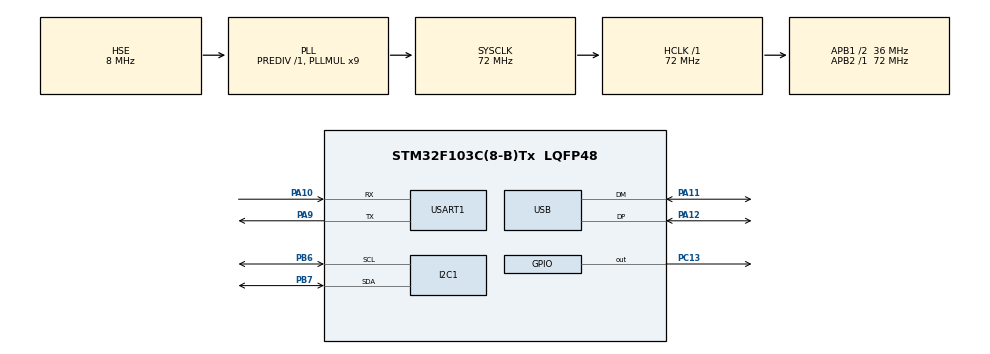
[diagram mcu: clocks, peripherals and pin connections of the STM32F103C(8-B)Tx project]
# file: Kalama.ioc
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FREERTOS.Tasks01=defaultTask,0,512,StartDefaultTask,Default,NULL,Dynamic,NULL,NULL
FREERTOS.configUSE_NEWLIB_REENTRANT=1
Mcu.Family=STM32F1
Mcu.Name=STM32F103C(8-B)Tx
Mcu.Package=LQFP48
NVIC.PriorityGroup=NVIC_PRIORITYGROUP_4
NVIC.TIM4_IRQn=true\:15\:0\:false\:false\:true\:false\:false\:true\:true
NVIC.TimeBase=TIM4_IRQn
NVIC.TimeBaseIP=TIM4
NVIC.USB_LP_CAN1_RX0_IRQn=true\:5\:0\:false\:false\:true\:true\:false\:true\:true
PA10.Mode=Asynchronous
PA10.Signal=USART1_RX
PA11.Mode=Device
PA11.Signal=USB_DM
PA12.Mode=Device
PA12.Signal=USB_DP
PA13.Mode=Trace_Asynchronous_SW
PA13.Signal=SYS_JTMS-SWDIO
PA14.Mode=Trace_Asynchronous_SW
PA14.Signal=SYS_JTCK-SWCLK
PA9.Mode=Asynchronous
PA9.Signal=USART1_TX
PB3.Mode=Trace_Asynchronous_SW
PB3.Signal=SYS_JTDO-TRACESWO
PB6.Mode=I2C
PB6.Signal=I2C1_SCL
PB7.Mode=I2C
PB7.Signal=I2C1_SDA
PC13-TAMPER-RTC.Signal=GPIO_Output
PC14-OSC32_IN.Mode=LSE-External-Oscillator
PC14-OSC32_IN.Signal=RCC_OSC32_IN
PC15-OSC32_OUT.Mode=LSE-External-Oscillator
PC15-OSC32_OUT.Signal=RCC_OSC32_OUT
PD0-OSC_IN.Mode=HSE-External-Oscillator
PD0-OSC_IN.Signal=RCC_OSC_IN
PD1-OSC_OUT.Mode=HSE-External-Oscillator
PD1-OSC_OUT.Signal=RCC_OSC_OUT
ProjectManager.HeapSize=0x4000
ProjectManager.StackSize=0x4000
ProjectManager.TargetToolchain=STM32CubeIDE
RCC.AHBFreq_Value=72000000
RCC.APB1CLKDivider=RCC_HCLK_DIV2
RCC.APB1Freq_Value=36000000
RCC.APB1TimFreq_Value=72000000
RCC.APB2Freq_Value=72000000
RCC.APB2TimFreq_Value=72000000
RCC.HCLKFreq_Value=72000000
RCC.PLLMUL=RCC_PLL_MUL9
RCC.SYSCLKFreq_VALUE=72000000
RCC.SYSCLKSource=RCC_SYSCLKSOURCE_PLLCLK
RCC.USBFreq_Value=48000000
RCC.USBPrescaler=RCC_USBCLKSOURCE_PLL_DIV1_5
USART1.VirtualMode=VM_ASYNC
USB_DEVICE.CLASS_NAME_FS=CDC
USB_DEVICE.MANUFACTURER_STRING=Sab1e
USB_DEVICE.PID_CDC_FS=0x0066
USB_DEVICE.PRODUCT_STRING_CDC_FS=Kalama
USB_DEVICE.VID=0x1234
USB_DEVICE.VirtualMode=Cdc
USB_DEVICE.VirtualModeFS=Cdc_FS
VP_FREERTOS_VS_CMSIS_V1.Mode=CMSIS_V1
VP_SYS_VS_tim4.Mode=TIM4
VP_USB_DEVICE_VS_USB_DEVICE_CDC_FS.Mode=CDC_FS
board=custom

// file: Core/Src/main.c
/* USER CODE BEGIN Header */
/**
 ******************************************************************************
 * @file           : main.c
 * @brief          : Main program body
 ******************************************************************************
 * @attention
 *
 * Copyright (c) 2024 STMicroelectronics.
 * All rights reserved.
 *
 * This software is licensed under terms that can be found in the LICENSE file
 * in the root directory of this software component.
 * If no LICENSE file comes with this software, it is provided AS-IS.
 *
 ******************************************************************************
 */
/* USER CODE END Header */
#include "main.h"
#include "cmsis_os.h"
#include "usb_device.h"

/* USER CODE BEGIN Includes */
#include "global.h"
/* USER CODE END Includes */

/* USER CODE BEGIN PD */
//#define I2C_SCAN_TIMEOUT 10  // 超时时间（单位：毫秒）
/* USER CODE END PD */

I2C_HandleTypeDef hi2c1;

UART_HandleTypeDef huart1;

osThreadId defaultTaskHandle;

void SystemClock_Config(void);
static void MX_GPIO_Init(void);
static void MX_I2C1_Init(void);
static void MX_USART1_UART_Init(void);
void StartDefaultTask(void const *argument);

/* USER CODE BEGIN 0 */

//void I2C_Scan(I2C_HandleTypeDef *hi2c)
//{
//    uint8_t i;
//    uint8_t deviceFound = 0;
//
//    uart_printf("Scanning I2C bus...\n");
//
//    // 扫描从0x03到0x77的所有7位地址（0x00-0x02和0x78-0x7F通常是保留地址）
//    for (i = 3; i < 0x78; i++)
//    {
//        // 检查设备是否响应
//        if (HAL_I2C_IsDeviceReady(hi2c, i << 1, 2, I2C_SCAN_TIMEOUT) == HAL_OK)
//        {
//        	uart_printf("Device found at address 0x%02X\n", i);
//            deviceFound = 1;
//        }
//    }
//
//    if (!deviceFound)
//    {
//    	uart_printf("No devices found on the I2C bus.\n");
//    }
//}
/* USER CODE END 0 */

int main(void) {

	/* MCU Configuration--------------------------------------------------------*/

	/* Reset of all peripherals, Initializes the Flash interface and the Systick. */
	HAL_Init();

	/* Configure the system clock */
	SystemClock_Config();

	/* Initialize all configured peripherals */
	MX_GPIO_Init();
	MX_I2C1_Init();
	MX_USART1_UART_Init();
	/* USER CODE BEGIN 2 */
//  I2C_Scan(&hi2c1);
	/* USER CODE END 2 */

	/* Create the thread(s) */
	/* definition and creation of defaultTask */
	osThreadDef(defaultTask, StartDefaultTask, osPriorityNormal, 0, 512);
	defaultTaskHandle = osThreadCreate(osThread(defaultTask), NULL);

	/* Start scheduler */
	osKernelStart();

	/* We should never get here as control is now taken by the scheduler */

	/* Infinite loop */
	while (1) {

	}
}

void SystemClock_Config(void) {
	RCC_OscInitTypeDef RCC_OscInitStruct = { 0 };
	RCC_ClkInitTypeDef RCC_ClkInitStruct = { 0 };
	RCC_PeriphCLKInitTypeDef PeriphClkInit = { 0 };

	/** Initializes the RCC Oscillators according to the specified parameters
	 * in the RCC_OscInitTypeDef structure.
	 */
	RCC_OscInitStruct.OscillatorType = RCC_OSCILLATORTYPE_HSE;
	RCC_OscInitStruct.HSEState = RCC_HSE_ON;
	RCC_OscInitStruct.HSEPredivValue = RCC_HSE_PREDIV_DIV1;
	RCC_OscInitStruct.HSIState = RCC_HSI_ON;
	RCC_OscInitStruct.PLL.PLLState = RCC_PLL_ON;
	RCC_OscInitStruct.PLL.PLLSource = RCC_PLLSOURCE_HSE;
	RCC_OscInitStruct.PLL.PLLMUL = RCC_PLL_MUL9;
	if (HAL_RCC_OscConfig(&RCC_OscInitStruct) != HAL_OK) {
		Error_Handler();
	}

	/** Initializes the CPU, AHB and APB buses clocks
	 */
	RCC_ClkInitStruct.ClockType = RCC_CLOCKTYPE_HCLK | RCC_CLOCKTYPE_SYSCLK
					| RCC_CLOCKTYPE_PCLK1 | RCC_CLOCKTYPE_PCLK2;
	RCC_ClkInitStruct.SYSCLKSource = RCC_SYSCLKSOURCE_PLLCLK;
	RCC_ClkInitStruct.AHBCLKDivider = RCC_SYSCLK_DIV1;
	RCC_ClkInitStruct.APB1CLKDivider = RCC_HCLK_DIV2;
	RCC_ClkInitStruct.APB2CLKDivider = RCC_HCLK_DIV1;

	if (HAL_RCC_ClockConfig(&RCC_ClkInitStruct, FLASH_LATENCY_2) != HAL_OK) {
		Error_Handler();
	}
	PeriphClkInit.PeriphClockSelection = RCC_PERIPHCLK_USB;
	PeriphClkInit.UsbClockSelection = RCC_USBCLKSOURCE_PLL_DIV1_5;
	if (HAL_RCCEx_PeriphCLKConfig(&PeriphClkInit) != HAL_OK) {
		Error_Handler();
	}
}

static void MX_I2C1_Init(void) {

	hi2c1.Instance = I2C1;
	hi2c1.Init.ClockSpeed = 100000;
	hi2c1.Init.DutyCycle = I2C_DUTYCYCLE_2;
	hi2c1.Init.OwnAddress1 = 0;
	hi2c1.Init.AddressingMode = I2C_ADDRESSINGMODE_7BIT;
	hi2c1.Init.DualAddressMode = I2C_DUALADDRESS_DISABLE;
	hi2c1.Init.OwnAddress2 = 0;
	hi2c1.Init.GeneralCallMode = I2C_GENERALCALL_DISABLE;
	hi2c1.Init.NoStretchMode = I2C_NOSTRETCH_DISABLE;
	if (HAL_I2C_Init(&hi2c1) != HAL_OK) {
		Error_Handler();
	}

}

static void MX_USART1_UART_Init(void) {

	huart1.Instance = USART1;
	huart1.Init.BaudRate = 115200;
	huart1.Init.WordLength = UART_WORDLENGTH_8B;
	huart1.Init.StopBits = UART_STOPBITS_1;
	huart1.Init.Parity = UART_PARITY_NONE;
	huart1.Init.Mode = UART_MODE_TX_RX;
	huart1.Init.HwFlowCtl = UART_HWCONTROL_NONE;
	huart1.Init.OverSampling = UART_OVERSAMPLING_16;
	if (HAL_UART_Init(&huart1) != HAL_OK) {
		Error_Handler();
	}

}

static void MX_GPIO_Init(void) {
	GPIO_InitTypeDef GPIO_InitStruct = { 0 };

	/* GPIO Ports Clock Enable */
	__HAL_RCC_GPIOC_CLK_ENABLE();
	__HAL_RCC_GPIOD_CLK_ENABLE();
	__HAL_RCC_GPIOA_CLK_ENABLE();
	__HAL_RCC_GPIOB_CLK_ENABLE();

	/*Configure GPIO pin Output Level */
	HAL_GPIO_WritePin(GPIOC, GPIO_PIN_13, GPIO_PIN_RESET);

	/*Configure GPIO pin : PC13 */
	GPIO_InitStruct.Pin = GPIO_PIN_13;
	GPIO_InitStruct.Mode = GPIO_MODE_OUTPUT_PP;
	GPIO_InitStruct.Pull = GPIO_NOPULL;
	GPIO_InitStruct.Speed = GPIO_SPEED_FREQ_LOW;
	HAL_GPIO_Init(GPIOC, &GPIO_InitStruct);

}

/* USER CODE BEGIN 4 */
float temp = 0.0;
/* USER CODE END 4 */

void StartDefaultTask(void const *argument) {
	/* init code for USB_DEVICE */
	MX_USB_DEVICE_Init();
	/* USER CODE BEGIN 5 */
	while (AMG8833_Init(&hi2c1, AMG8833_I2C_ADDRESS) != AMGD_OK) {
		HAL_GPIO_TogglePin(LED_GPIO, LED_GPIO_PIN);
		osDelay(100);
	}
	HAL_GPIO_WritePin(LED_GPIO, LED_GPIO_PIN, RESET);
	uint8_t buffer[8][16] = { 0 };
	/* Infinite loop */
	for (;;) {
		osDelay(1);
		AMG8833_ReadThermography(buffer);
		CDC_Transmit_FS((uint8_t*) buffer, sizeof(buffer));
	}
	/* USER CODE END 5 */
}

void HAL_TIM_PeriodElapsedCallback(TIM_HandleTypeDef *htim) {
	if (htim->Instance == TIM4) {
		HAL_IncTick();
	}
}

void Error_Handler(void) {
	__disable_irq();
	while (1) {
	}
}
